# NVMCALIB register map
Registers are 32-bit, read, no defined reset value unless marked. A register's access mark holds for its fields unless they carry their own. Offsets are from the block's base; lines under a group give offsets from that group; [hi:lo] are bit positions; {n}, {i} and the like mark numbered series; 'fields as' and 'values as' point back to an identical list; <NAME> marks a mode.

## Memory map
0x00806020 NVMCALIB — 24Bit System Tick Timer for use in RTOS

## NVMCALIB — 24Bit System Tick Timer for use in RTOS
Base 0x00806020
0x00 SOFT0 — Calibration data that are measured and written during production test, index 0
  [31:27] ADC_LINEARITY_LSB — ADC Linearity Calibration, bits 0..4. Should be written to CALIB register.
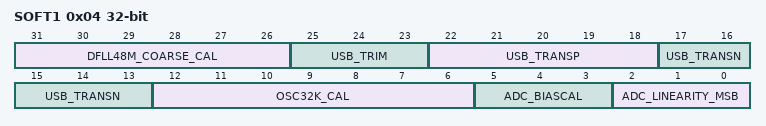
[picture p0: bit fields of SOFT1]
0x04 SOFT1 — Calibration data that are measured and written during production test, index 1
  [31:26] DFLL48M_COARSE_CAL — DFLL48M Coarse calibration value. Should be written to the SYSCTRL DFLLVAL register.
  [25:23] USB_TRIM — USB TRIM calibration value. Should be written to the USB PADCAL register.
  [22:18] USB_TRANSP — USB TRANSP calibration value. Should be written to the USB PADCAL register.
  [17:13] USB_TRANSN — USB TRANSN calibration value. Should be written to the USB PADCAL register.
  [12:6] OSC32K_CAL — OSC32KCalibration. Should be written to OSC32K register.
  [5:3] ADC_BIASCAL — ADC Bias Calibration. Should be written to CALIB register.
  [2:0] ADC_LINEARITY_MSB — ADC Linearity Calibration, bits 5..7. Should be written to CALIB register.
